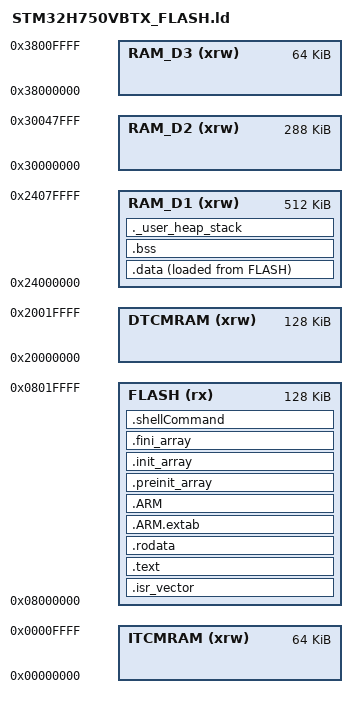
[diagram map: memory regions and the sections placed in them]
/**
 ******************************************************************************
 * @file      LinkerScript.ld
 * @author    Auto-generated by STM32CubeIDE
 * @brief     Linker script for STM32H750VBTx Device from STM32H7 series
 *                      128Kbytes FLASH
 *                      128Kbytes DTCMRAM
 *                      64Kbytes ITCMRAM
 *                      512Kbytes RAM_D1
 *                      288Kbytes RAM_D2
 *                      64Kbytes RAM_D3
 *
 *            Set heap size, stack size and stack location according
 *            to application requirements.
 *
 *            Set memory bank area and size if external memory is used
 ******************************************************************************
 * @attention
 *
 * <h2><center>&copy; Copyright (c) 2020 STMicroelectronics.
 * All rights reserved.</center></h2>
 *
 * This software component is licensed by ST under BSD 3-Clause license,
 * the "License"; You may not use this file except in compliance with the
 * License. You may obtain a copy of the License at:
 *                        opensource.org/licenses/BSD-3-Clause
 *
 ******************************************************************************
 */

/* Entry Point 定义程序入口地址*/
ENTRY(Reset_Handler)

/* Highest address of the user mode stack */
/* 栈变量_estack（汇编文件会使用这个变量），
 * ORIGIN获取指定内存区域的地址，LENGTH获取指定内存区域的大小
 * ORIGIN(RAM_D1) + LENGTH(RAM_D1)获取到指定内存的最大地址，实现栈的向下生长 */
_estack = ORIGIN(RAM_D1) + LENGTH(RAM_D1);	/* end of "RAM_D1" Ram type memory */

/* 定义最小的堆栈 */
_Min_Heap_Size = 0x200 ;	/* required amount of heap  */
_Min_Stack_Size = 0x400 ;	/* required amount of stack */

/* Memories definition */
/* MEMORY关键字，用于定义可用的内存区域及属性
 * xrw表示可读可写，rx表示制度 */
MEMORY
{
  DTCMRAM    (xrw)    : ORIGIN = 0x20000000,   LENGTH = 128K
  ITCMRAM    (xrw)    : ORIGIN = 0x00000000,   LENGTH = 64K
  RAM_D1    (xrw)    : ORIGIN = 0x24000000,   LENGTH = 512K
  RAM_D2    (xrw)    : ORIGIN = 0x30000000,   LENGTH = 288K
  RAM_D3    (xrw)    : ORIGIN = 0x38000000,   LENGTH = 64K
  FLASH    (rx)    : ORIGIN = 0x8000000,   LENGTH = 128K
}

/* Sections */
/* SECTIONS关键字，用于定义各个段的布局和排列
 * '.' 表示当前内存位置
 * '>' 指定段的存放位置
 * 'ALIGN' 设置字节对齐
 */
SECTIONS
{
  /* The startup code into "FLASH" Rom type memory */
  /* 中断向量表 */
  .isr_vector :
  {
    /* 设置当前地址的对齐方式 */
    . = ALIGN(4);
    /* 保持段或符号不被丢失 */
    KEEP(*(.isr_vector)) /* Startup code */
    . = ALIGN(4);
  } >FLASH /* 将isr_vector段放置在FLASH内存区域 */

  /* The program code and other data into "FLASH" Rom type memory */
  /* 代码段 */
  .text :
  {
    . = ALIGN(4);
    *(.text)           /* .text sections (code) */
    /* 包含所有以.text开头的段 */
    *(.text*)          /* .text* sections (code) */
    *(.glue_7)         /* glue arm to thumb code */
    *(.glue_7t)        /* glue thumb to arm code */
    *(.eh_frame)

    /* 保证所有.init的段不被优化 */
    KEEP (*(.init))
    KEEP (*(.fini))

    . = ALIGN(4);
    _etext = .;        /* define a global symbols at end of code */
  } >FLASH

  /* Constant data into "FLASH" Rom type memory */
  /* 只读数据 */
  .rodata :
  {
    . = ALIGN(4);
    *(.rodata)         /* .rodata sections (constants, strings, etc.) */
    *(.rodata*)        /* .rodata* sections (constants, strings, etc.) */
    . = ALIGN(4);
  } >FLASH

  .ARM.extab   : { 
    . = ALIGN(4);
    *(.ARM.extab* .gnu.linkonce.armextab.*)
    . = ALIGN(4);
  } >FLASH
  
  .ARM : {
    . = ALIGN(4);
    __exidx_start = .;
    *(.ARM.exidx*)
    __exidx_end = .;
    . = ALIGN(4);
  } >FLASH

  .preinit_array     :
  {
    . = ALIGN(4);
    PROVIDE_HIDDEN (__preinit_array_start = .);
    KEEP (*(.preinit_array*))
    PROVIDE_HIDDEN (__preinit_array_end = .);
    . = ALIGN(4);
  } >FLASH
  
  .init_array :
  {
    . = ALIGN(4);
    PROVIDE_HIDDEN (__init_array_start = .);
    KEEP (*(SORT(.init_array.*)))
    KEEP (*(.init_array*))
    PROVIDE_HIDDEN (__init_array_end = .);
    . = ALIGN(4);
  } >FLASH
  
  .fini_array :
  {
    . = ALIGN(4);
    PROVIDE_HIDDEN (__fini_array_start = .);
    KEEP (*(SORT(.fini_array.*)))
    KEEP (*(.fini_array*))
    PROVIDE_HIDDEN (__fini_array_end = .);
    . = ALIGN(4);
  } >FLASH

  .shellCommand :
  {
    . = ALIGN(4);
    _shell_command_start = .;
    KEEP (*(shellCommand))
    _shell_command_end = .;
    . = ALIGN(4);
  } >FLASH

  /* Used by the startup to initialize data */
  _sidata = LOADADDR(.data);

  /* Initialized data sections into "RAM_D1" Ram type memory */
  .data : 
  {
    . = ALIGN(4);
    _sdata = .;        /* create a global symbol at data start */
    *(.data)           /* .data sections */
    *(.data*)          /* .data* sections */

    . = ALIGN(4);
    _edata = .;        /* define a global symbol at data end */
    
  } >RAM_D1 AT> FLASH

  /* Uninitialized data section into "RAM_D1" Ram type memory */
  . = ALIGN(4);
  .bss :
  {
    /* This is used by the startup in order to initialize the .bss section */
    _sbss = .;         /* define a global symbol at bss start */
    __bss_start__ = _sbss;
    *(.bss)
    *(.bss*)
    *(COMMON)

    . = ALIGN(4);
    _ebss = .;         /* define a global symbol at bss end */
    __bss_end__ = _ebss;
  } >RAM_D1

  /* User_heap_stack section, used to check that there is enough "RAM_D1" Ram  type memory left */
  ._user_heap_stack :
  {
    . = ALIGN(8);
    PROVIDE ( end = . );
    PROVIDE ( _end = . );
    . = . + _Min_Heap_Size;
    . = . + _Min_Stack_Size;
    . = ALIGN(8);
  } >RAM_D1

  /* Remove information from the compiler libraries */
  /DISCARD/ :
  {
    libc.a ( * )
    libm.a ( * )
    libgcc.a ( * )
  }

  .ARM.attributes 0 : { *(.ARM.attributes) }
}
